# STM32WL54CCU6@M0 register map
File version: 1.0
Registers are 32-bit, access not given, reset 0x0 unless marked. A register's access mark holds for its fields unless they carry their own. Offsets are from the block's base; [hi:lo] are bit positions; 'fields as' and 'values as' point back to an identical list.

## RCC
Base 0x58000000
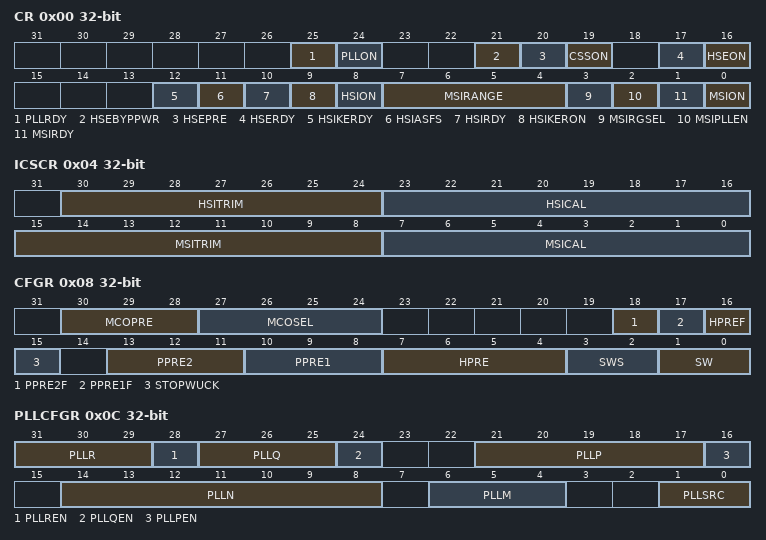
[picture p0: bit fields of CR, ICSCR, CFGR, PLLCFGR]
0x00 CR
  [25] PLLRDY, [24] PLLON, [21] HSEBYPPWR, [20] HSEPRE, [19] CSSON, [17] HSERDY, [16] HSEON, [12] HSIKERDY, [11] HSIASFS, [10] HSIRDY, [9] HSIKERON, [8] HSION, [7:4] MSIRANGE, [3] MSIRGSEL, [2] MSIPLLEN, [1] MSIRDY, [0] MSION
0x04 ICSCR
  [30:24] HSITRIM, [23:16] HSICAL, [15:8] MSITRIM, [7:0] MSICAL
0x08 CFGR
  [30:28] MCOPRE, [27:24] MCOSEL, [18] PPRE2F, [17] PPRE1F, [16] HPREF, [15] STOPWUCK, [13:11] PPRE2, [10:8] PPRE1, [7:4] HPRE, [3:2] SWS, [1:0] SW
0x0C PLLCFGR
  [31:29] PLLR, [28] PLLREN, [27:25] PLLQ, [24] PLLQEN, [21:17] PLLP, [16] PLLPEN, [14:8] PLLN, [6:4] PLLM, [1:0] PLLSRC
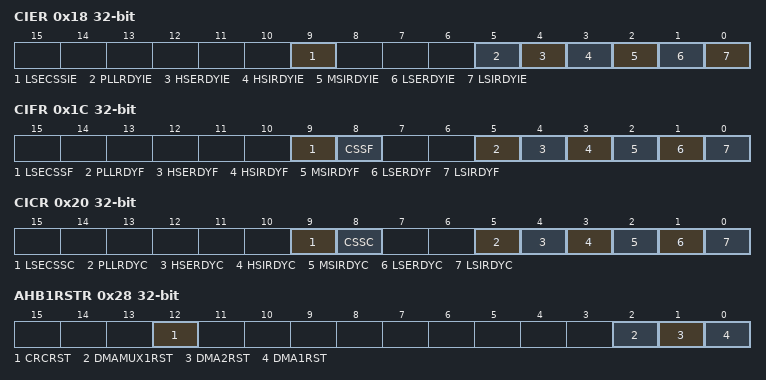
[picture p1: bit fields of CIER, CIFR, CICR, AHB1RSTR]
0x18 CIER
  [9] LSECSSIE, [5] PLLRDYIE, [4] HSERDYIE, [3] HSIRDYIE, [2] MSIRDYIE, [1] LSERDYIE, [0] LSIRDYIE
0x1C CIFR
  [9] LSECSSF, [8] CSSF, [5] PLLRDYF, [4] HSERDYF, [3] HSIRDYF, [2] MSIRDYF, [1] LSERDYF, [0] LSIRDYF
0x20 CICR
  [9] LSECSSC, [8] CSSC, [5] PLLRDYC, [4] HSERDYC, [3] HSIRDYC, [2] MSIRDYC, [1] LSERDYC, [0] LSIRDYC
0x28 AHB1RSTR
  [12] CRCRST, [2] DMAMUX1RST, [1] DMA2RST, [0] DMA1RST
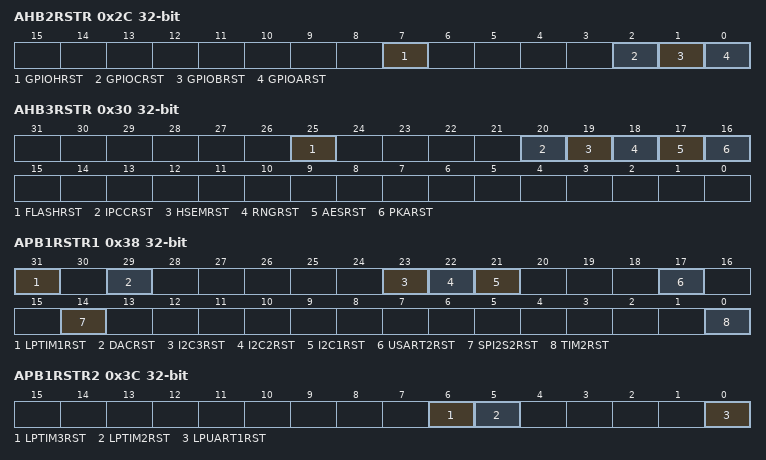
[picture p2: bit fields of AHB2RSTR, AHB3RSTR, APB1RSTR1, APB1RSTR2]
0x2C AHB2RSTR
  [7] GPIOHRST, [2] GPIOCRST, [1] GPIOBRST, [0] GPIOARST
0x30 AHB3RSTR
  [25] FLASHRST, [20] IPCCRST, [19] HSEMRST, [18] RNGRST, [17] AESRST, [16] PKARST
0x38 APB1RSTR1
  [31] LPTIM1RST, [29] DACRST, [23] I2C3RST, [22] I2C2RST, [21] I2C1RST, [17] USART2RST, [14] SPI2S2RST, [0] TIM2RST
0x3C APB1RSTR2
  [6] LPTIM3RST, [5] LPTIM2RST, [0] LPUART1RST
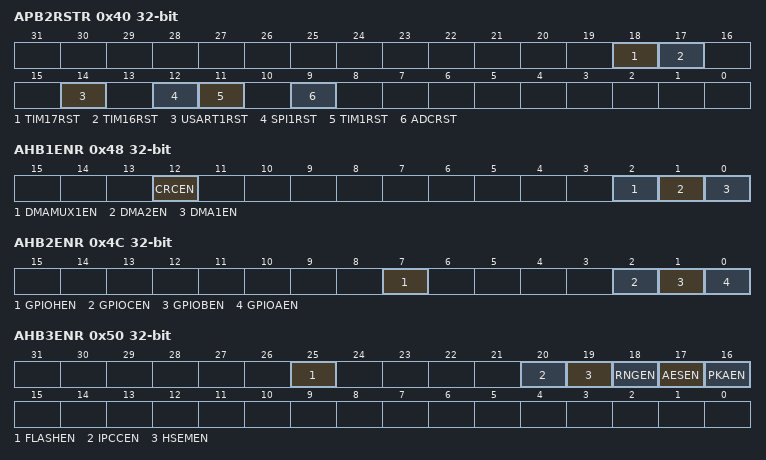
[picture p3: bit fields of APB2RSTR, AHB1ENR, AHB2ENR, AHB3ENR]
0x40 APB2RSTR
  [18] TIM17RST, [17] TIM16RST, [14] USART1RST, [12] SPI1RST, [11] TIM1RST, [9] ADCRST
0x44 APB3RSTR
  [0] SUBGHZSPIRST
0x48 AHB1ENR
  [12] CRCEN, [2] DMAMUX1EN, [1] DMA2EN, [0] DMA1EN
0x4C AHB2ENR
  [7] GPIOHEN, [2] GPIOCEN, [1] GPIOBEN, [0] GPIOAEN
0x50 AHB3ENR
  [25] FLASHEN, [20] IPCCEN, [19] HSEMEN, [18] RNGEN, [17] AESEN, [16] PKAEN
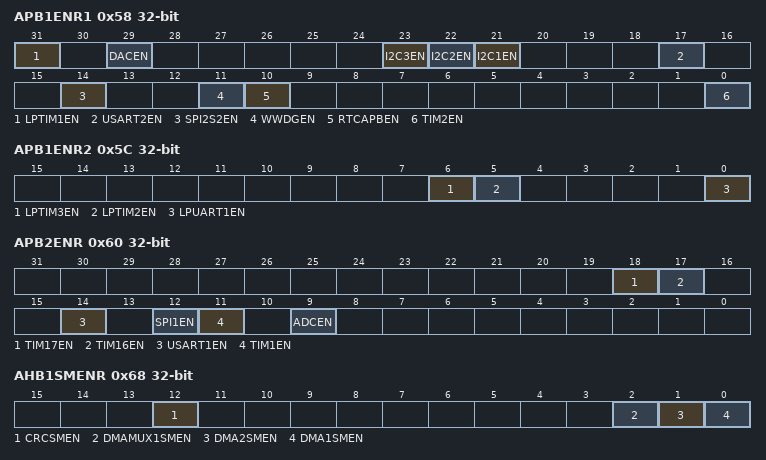
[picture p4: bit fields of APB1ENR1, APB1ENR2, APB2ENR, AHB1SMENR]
0x58 APB1ENR1
  [31] LPTIM1EN, [29] DACEN, [23] I2C3EN, [22] I2C2EN, [21] I2C1EN, [17] USART2EN, [14] SPI2S2EN, [11] WWDGEN, [10] RTCAPBEN, [0] TIM2EN
0x5C APB1ENR2
  [6] LPTIM3EN, [5] LPTIM2EN, [0] LPUART1EN
0x60 APB2ENR
  [18] TIM17EN, [17] TIM16EN, [14] USART1EN, [12] SPI1EN, [11] TIM1EN, [9] ADCEN
0x64 APB3ENR
  [0] SUBGHZSPIEN
0x68 AHB1SMENR
  [12] CRCSMEN, [2] DMAMUX1SMEN, [1] DMA2SMEN, [0] DMA1SMEN
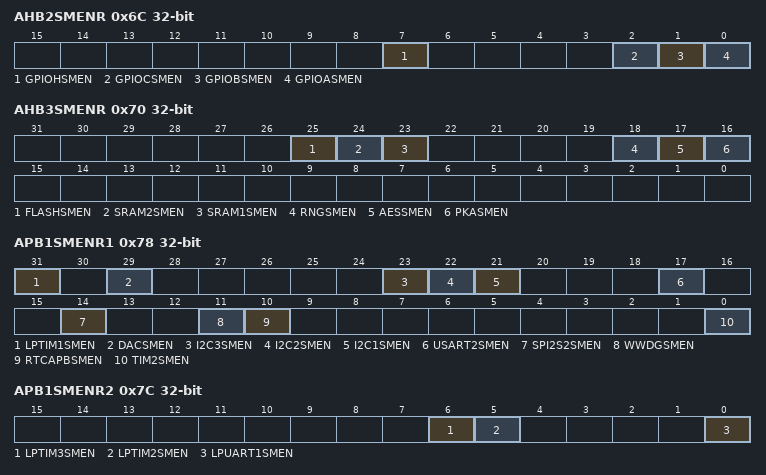
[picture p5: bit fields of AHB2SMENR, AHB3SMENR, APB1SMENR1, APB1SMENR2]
0x6C AHB2SMENR
  [7] GPIOHSMEN, [2] GPIOCSMEN, [1] GPIOBSMEN, [0] GPIOASMEN
0x70 AHB3SMENR
  [25] FLASHSMEN, [24] SRAM2SMEN, [23] SRAM1SMEN, [18] RNGSMEN, [17] AESSMEN, [16] PKASMEN
0x78 APB1SMENR1
  [31] LPTIM1SMEN, [29] DACSMEN, [23] I2C3SMEN, [22] I2C2SMEN, [21] I2C1SMEN, [17] USART2SMEN, [14] SPI2S2SMEN, [11] WWDGSMEN, [10] RTCAPBSMEN, [0] TIM2SMEN
0x7C APB1SMENR2
  [6] LPTIM3SMEN, [5] LPTIM2SMEN, [0] LPUART1SMEN
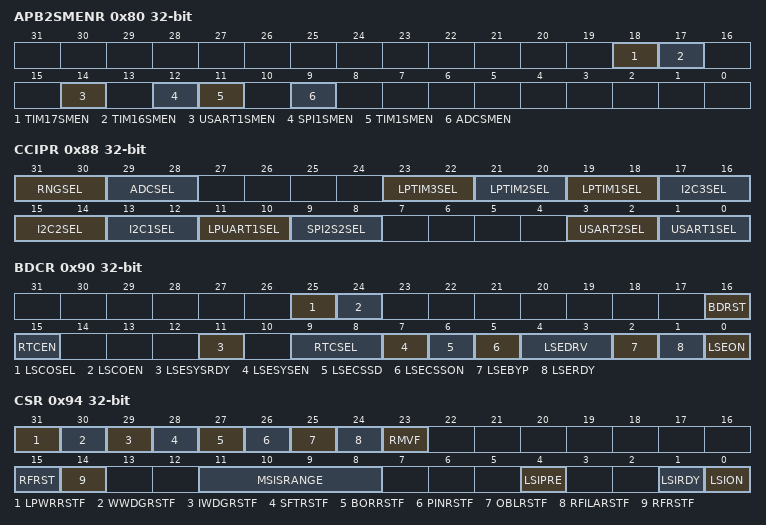
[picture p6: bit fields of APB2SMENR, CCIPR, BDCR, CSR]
0x80 APB2SMENR
  [18] TIM17SMEN, [17] TIM16SMEN, [14] USART1SMEN, [12] SPI1SMEN, [11] TIM1SMEN, [9] ADCSMEN
0x84 APB3SMENR
  [0] SUBGHZSPISMEN
0x88 CCIPR
  [31:30] RNGSEL, [29:28] ADCSEL, [23:22] LPTIM3SEL, [21:20] LPTIM2SEL, [19:18] LPTIM1SEL, [17:16] I2C3SEL, [15:14] I2C2SEL, [13:12] I2C1SEL, [11:10] LPUART1SEL, [9:8] SPI2S2SEL, [3:2] USART2SEL, [1:0] USART1SEL
0x90 BDCR
  [25] LSCOSEL, [24] LSCOEN, [16] BDRST, [15] RTCEN, [11] LSESYSRDY, [9:8] RTCSEL, [7] LSESYSEN, [6] LSECSSD, [5] LSECSSON, [4:3] LSEDRV, [2] LSEBYP, [1] LSERDY, [0] LSEON
0x94 CSR
  [31] LPWRRSTF, [30] WWDGRSTF, [29] IWDGRSTF, [28] SFTRSTF, [27] BORRSTF, [26] PINRSTF, [25] OBLRSTF, [24] RFILARSTF, [23] RMVF, [15] RFRST, [14] RFRSTF, [11:8] MSISRANGE, [4] LSIPRE, [1] LSIRDY, [0] LSION
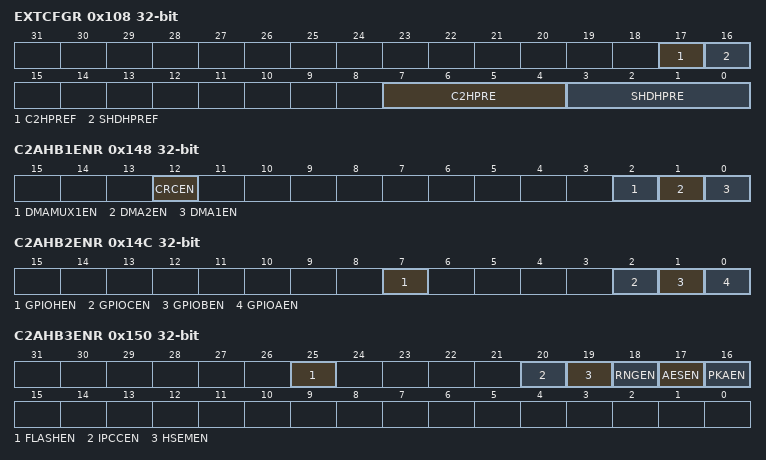
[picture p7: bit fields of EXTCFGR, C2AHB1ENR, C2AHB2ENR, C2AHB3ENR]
0x108 EXTCFGR
  [17] C2HPREF, [16] SHDHPREF, [7:4] C2HPRE, [3:0] SHDHPRE
0x148 C2AHB1ENR
  [12] CRCEN, [2] DMAMUX1EN, [1] DMA2EN, [0] DMA1EN
0x14C C2AHB2ENR
  [7] GPIOHEN, [2] GPIOCEN, [1] GPIOBEN, [0] GPIOAEN
0x150 C2AHB3ENR
  fields as AHB3ENR
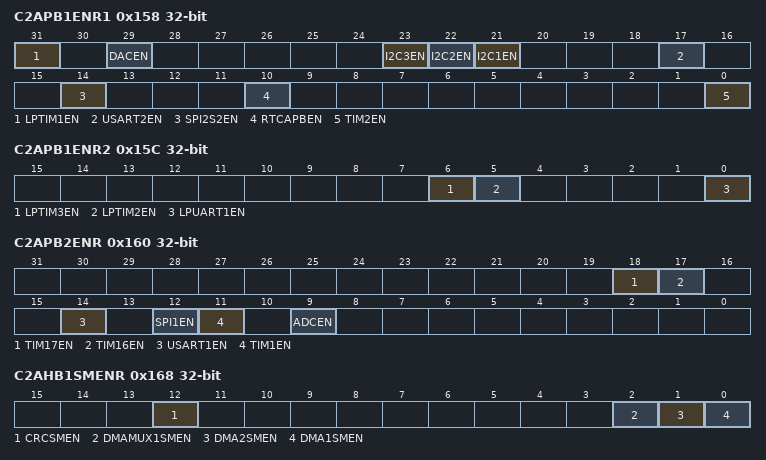
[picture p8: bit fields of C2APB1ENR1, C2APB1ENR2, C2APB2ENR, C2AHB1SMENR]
0x158 C2APB1ENR1
  [31] LPTIM1EN, [29] DACEN, [23] I2C3EN, [22] I2C2EN, [21] I2C1EN, [17] USART2EN, [14] SPI2S2EN, [10] RTCAPBEN, [0] TIM2EN
0x15C C2APB1ENR2
  [6] LPTIM3EN, [5] LPTIM2EN, [0] LPUART1EN
0x160 C2APB2ENR
  fields as APB2ENR
0x164 C2APB3ENR
  [0] SUBGHZSPIEN
0x168 C2AHB1SMENR
  [12] CRCSMEN, [2] DMAMUX1SMEN, [1] DMA2SMEN, [0] DMA1SMEN
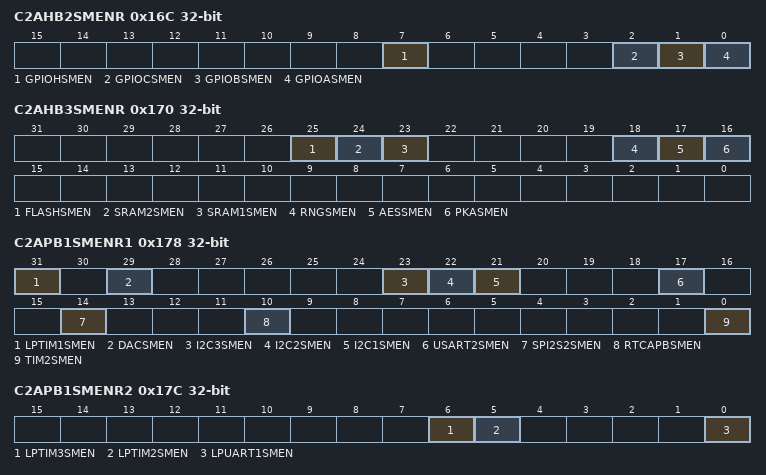
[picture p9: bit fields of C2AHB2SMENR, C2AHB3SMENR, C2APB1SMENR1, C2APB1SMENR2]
0x16C C2AHB2SMENR
  [7] GPIOHSMEN, [2] GPIOCSMEN, [1] GPIOBSMEN, [0] GPIOASMEN
0x170 C2AHB3SMENR
  fields as AHB3SMENR
0x178 C2APB1SMENR1
  [31] LPTIM1SMEN, [29] DACSMEN, [23] I2C3SMEN, [22] I2C2SMEN, [21] I2C1SMEN, [17] USART2SMEN, [14] SPI2S2SMEN, [10] RTCAPBSMEN, [0] TIM2SMEN
0x17C C2APB1SMENR2
  [6] LPTIM3SMEN, [5] LPTIM2SMEN, [0] LPUART1SMEN
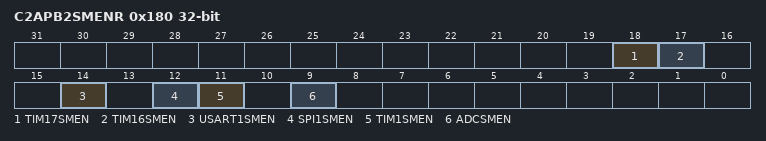
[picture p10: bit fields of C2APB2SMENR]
0x180 C2APB2SMENR
  fields as APB2SMENR
0x184 C2APB3SMENR
  [0] SUBGHZSPISMEN
